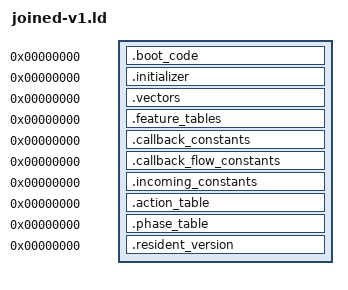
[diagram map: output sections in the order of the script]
OUTPUT_ARCH(riscv)
SECTIONS
{
 .boot_code 0 : SUBALIGN(2) { *(.boot_code)
  *(.text.tsl9_resident_startup_provider_188e2)
  *(.text.tsl9_peripheral_primitives_block_188f2)
  *(.text.tsl9_peripheral_primitives_block_188fc)
  *(.text.tsl9_peripheral_primitives_block_18902)
  *(.text.tsl9_peripheral_primitives_block_1890a)
  *(.text.tsl9_peripheral_primitives_block_18916)
  *(.text.tsl9_peripheral_primitives_block_18920)
  *(.text.tsl9_peripheral_primitives_block_18928)
  *(.text.tsl9_resident_startup_provider_1892e)
  *(.text.tsl9_resident_startup_provider_18986)
  *(.text.tsl9_peripheral_primitives_block_1898a)
  *(.text.tsl9_peripheral_primitives_block_1898e)
  *(.text.tsl9_peripheral_primitives_block_18992)
  *(.text.tsl9_resident_startup_provider_18996)
  *(.text.tsl9_peripheral_primitives_block_1899a)
  *(.text.tsl9_peripheral_primitives_block_189a0)
  *(.text.tsl9_peripheral_primitives_block_189a4)
  *(.text.tsl9_resident_startup_provider_189ae)
  *(.text.tsl9_peripheral_primitives_block_189b4)
  *(.text.tsl9_peripheral_primitives_block_189d8)
  *(.text.tsl9_peripheral_primitives_block_189de)
  *(.text.tsl9_peripheral_primitives_block_189fe)
  *(.text.tsl9_peripheral_primitives_block_18a20)
  *(.text.tsl9_peripheral_primitives_block_18a26)
  *(.text.tsl9_peripheral_primitives_block_18a46)
  *(.text.tsl9_resident_startup_provider_18a66)
  *(.text.tsl9_resident_startup_provider_18a6e)
  *(.text.tsl9_peripheral_primitives_block_18a7a)
  *(.text.tsl9_peripheral_primitives_block_18a80)
  *(.text.tsl9_peripheral_primitives_block_18a84)
  *(.text.tsl9_resident_startup_provider_18a8e)
  *(.text.tsl9_resident_startup_provider_18a98)
  *(.text.tsl9_peripheral_primitives_block_18a9c)
  *(.text.tsl9_peripheral_primitives_block_18aa2)
  *(.text.tsl9_peripheral_primitives_block_18aa6)
  *(.text.tsl9_resident_startup_provider_18f56)
  *(.text.tsl9_resident_startup_provider_19076)
  *(.text.tsl9_peripheral_primitives_block_1907e)
  *(.text.tsl9_peripheral_primitives_block_19082)
  *(.text.tsl9_peripheral_primitives_block_19086)
  *(.text.tsl9_resident_startup_provider_1908c)
  *(.text.tsl9_resident_startup_provider_1909e)
  *(.text.tsl9_peripheral_primitives_block_190b0)
  *(.text.tsl9_peripheral_primitives_block_190b6)
  *(.text.tsl9_peripheral_primitives_block_190b8)
  *(.text.tsl9_peripheral_primitives_block_190be)
  *(.text.tsl9_resident_startup_provider_190c6)
  *(.text.tsl9_peripheral_primitives_block_190ce)
  *(.text.tsl9_peripheral_primitives_block_190d2)
  *(.text.tsl9_peripheral_primitives_block_190d6)
  *(.text.tsl9_resident_startup_provider_190da)
  *(.text.tsl9_resident_startup_provider_190e6)
  *(.text.tsl9_peripheral_primitives_block_190e8)
  *(.text.tsl9_peripheral_primitives_block_190f6)
  *(.text.tsl9_resident_startup_provider_19106)
  *(.text.tsl9_peripheral_primitives_block_19108)
  *(.text.tsl9_peripheral_primitives_block_19114)
  *(.text.tsl9_peripheral_primitives_provider_1919c)
  *(.text.tsl9_peripheral_primitives_provider_191ae)
  *(.text.tsl9_resident_startup_provider_191c6)
  *(.text.tsl9_peripheral_primitives_block_191ca)
  *(.text.tsl9_peripheral_primitives_block_191da)
  *(.text.tsl9_peripheral_primitives_block_191de)
  *(.text.tsl9_peripheral_primitives_block_191ee)
  *(.text.tsl9_peripheral_primitives_block_191f2)
  *(.text.tsl9_peripheral_primitives_block_19202)
  *(.text.tsl9_peripheral_primitives_block_19206)
  *(.text.tsl9_peripheral_primitives_block_1920a)
  *(.text.tsl9_peripheral_primitives_block_1921a)
  *(.text.tsl9_resident_startup_provider_19220)
  *(.text.tsl9_peripheral_primitives_block_1922a)
  *(.text.tsl9_resident_startup_provider_19248)
  *(.text.tsl9_peripheral_primitives_block_19252)
  *(.text.tsl9_resident_startup_provider_1929a)
  *(.text.tsl9_peripheral_primitives_block_19316)
  *(.text.tsl9_peripheral_primitives_block_1933e)
  *(.text.tsl9_peripheral_primitives_block_1934a)
  *(.text.tsl9_peripheral_primitives_block_19386)
  *(.text.tsl9_peripheral_primitives_block_19388)
  *(.text.tsl9_peripheral_primitives_block_1938e)
  *(.text.tsl9_peripheral_primitives_block_19394)
  *(.text.tsl9_peripheral_primitives_block_193a0)
  *(.text.tsl9_peripheral_primitives_block_193ac)
  *(.text.tsl9_peripheral_primitives_block_193b8)
  *(.text.tsl9_peripheral_primitives_block_193d2)
  *(.text.tsl9_peripheral_primitives_block_193d6)
  *(.text.tsl9_peripheral_primitives_block_193e0)
  *(.text.tsl9_peripheral_primitives_block_193ec)
  *(.text.tsl9_peripheral_primitives_block_193ee)
  *(.text.tsl9_peripheral_primitives_block_19402)
  *(.text.tsl9_peripheral_primitives_block_19406)
  *(.text.tsl9_peripheral_primitives_block_19456)
  *(.text.tsl9_peripheral_primitives_block_19466)
  *(.text.tsl9_peripheral_primitives_block_1949e)
  *(.text.tsl9_peripheral_primitives_block_194a0)
  *(.text.tsl9_peripheral_primitives_block_194a4)
  *(.text.tsl9_peripheral_primitives_block_194a8)
  *(.text.tsl9_peripheral_primitives_block_194bc)
  *(.text.tsl9_peripheral_primitives_block_194c8)
  *(.text.tsl9_peripheral_primitives_block_194cc)
  *(.text.tsl9_peripheral_primitives_block_194d8)
  *(.text.tsl9_peripheral_primitives_block_19528)
  *(.text.tsl9_peripheral_primitives_block_1952a)
  *(.text.tsl9_peripheral_primitives_block_19592)
  *(.text.tsl9_peripheral_primitives_block_195a2)
  *(.text.tsl9_peripheral_primitives_block_195da)
  *(.text.tsl9_peripheral_primitives_block_195dc)
  *(.text.tsl9_peripheral_primitives_block_195e0)
  *(.text.tsl9_peripheral_primitives_block_195e4)
  *(.text.tsl9_peripheral_primitives_block_195f8)
  *(.text.tsl9_peripheral_primitives_block_19604)
  *(.text.tsl9_peripheral_primitives_block_19608)
  *(.text.tsl9_peripheral_primitives_block_19614)
  *(.text.tsl9_peripheral_primitives_block_19682)
  *(.text.tsl9_peripheral_primitives_block_19684)
  *(.text.tsl9_peripheral_primitives_block_196bc)
  *(.text.tsl9_peripheral_primitives_block_196c0)
  *(.text.tsl9_resident_startup_provider_19764)
  *(.text.tsl9_peripheral_primitives_block_1978c)
  *(.text.tsl9_peripheral_primitives_block_19792)
 }
 .initializer 0 : SUBALIGN(4) { *(.initializer) }
 .vectors 0 : SUBALIGN(4) { *(.vectors) }
 .feature_tables 0 : SUBALIGN(4) { *(.feature_tables) }
 .callback_constants 0 : SUBALIGN(4) { *(.callback_constants) }
 .callback_flow_constants 0 : SUBALIGN(4) { *(.callback_flow_constants) }
 .incoming_constants 0 : SUBALIGN(4) { *(.incoming_constants) }
 .action_table 0 : SUBALIGN(4) { *(.action_table) }
 .phase_table 0 : SUBALIGN(4) { *(.phase_table) }
 .resident_version 0 : SUBALIGN(4) { *(.resident_version) }
 /DISCARD/ : { *(.comment) *(.riscv.attributes) *(.llvm_addrsig) }
}
